# EDMA_TPCC_52A00000h register map
Vendor: Texas Instruments
Registers are 32-bit, read-only, reset 0x0 unless marked. A register's access mark holds for its fields unless they carry their own. Offsets are as the file gives them; [hi:lo] are bit positions; {n}, {i} and the like mark numbered series; 'fields as' and 'values as' point back to an identical list.

## TPCC (part 2 of 2)
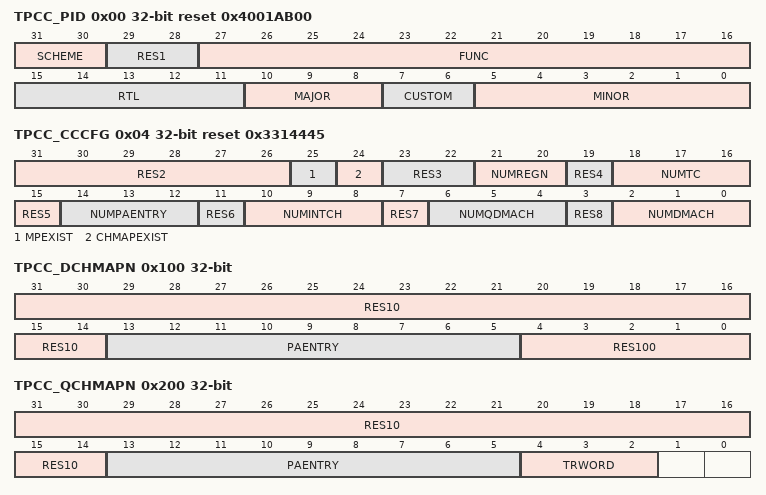
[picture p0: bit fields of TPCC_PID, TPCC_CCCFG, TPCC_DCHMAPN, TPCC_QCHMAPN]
0x00 TPCC_PID reset 0x4001AB00 — Peripheral ID Register
  [31:30] SCHEME — PID Scheme: Used to distinguish between old ID scheme and current. Spare bit to encode future schemes EDMA uses 'new scheme' indicated with value of 0x1.
  [29:28] RES1 — RESERVE FIELD
  [27:16] FUNC — Function indicates a software compatible module family.
  [15:11] RTL — RTL Version
  [10:8] MAJOR — Major Revision
  [7:6] CUSTOM — Custom revision field: Not used on this version of EDMA.
  [5:0] MINOR — Minor Revision
0x04 TPCC_CCCFG reset 0x3314445 — CC Configuration Register
  [31:26] RES2 — RESERVE FIELD
  [25] MPEXIST — Memory Protection Existence MPEXIST =0 : No memory protection. MPEXIST =1 : Memory Protection logic included.
  [24] CHMAPEXIST — Channel Mapping Existence CHMAPEXIST =0 : No Channel mapping. CHMAPEXIST =1 : Channel mapping logic included.
  [23:22] RES3 — RESERVE FIELD
  [21:20] NUMREGN — Number of MP and Shadow regions
  [35-4n] RES{n} (n=4..8) — RESERVE FIELD
  [18:16] NUMTC — Number of Queues/Number of TCs
  [14:12] NUMPAENTRY — Number of PaRAM entries
  [10:8] NUMINTCH — Number of Interrupt Channels
  [6:4] NUMQDMACH — Number of QDMA Channels
  [2:0] NUMDMACH — Number of DMA Channels
0x100 TPCC_DCHMAPN access per field — DMA Channel N mapping to PaRAM.
  [31:14] RES10 ro — RESERVE FIELD
  [13:5] PAENTRY rw — PAENTRY points to the PaRAM Entry number for DMA Channel N
  [4:0] RES100 ro — RESERVE FIELD
0x200 TPCC_QCHMAPN access per field — QDMA Channel N Mapping Register
  [31:14] RES10 ro — RESERVE FIELD
  [13:5] PAENTRY rw — PaRAM Entry number for QDMA Channel N.
  [4:2] TRWORD rw — TRWORD points to the specific trigger word of the PaRAM Entry defined by PAENTRY. A write to the trigger word results in a QDMA Event being recognized.
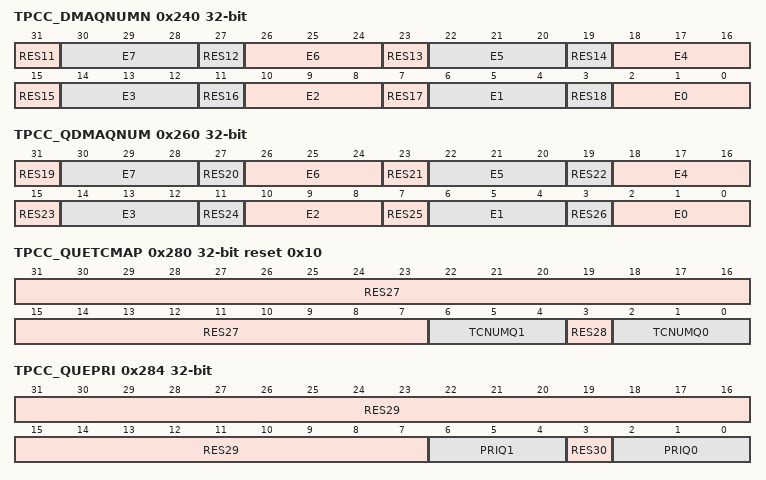
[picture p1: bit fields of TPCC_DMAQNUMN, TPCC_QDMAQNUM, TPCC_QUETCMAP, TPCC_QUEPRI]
0x240 TPCC_DMAQNUMN access per field — DMA Queue Number Register n Contains the Event queue number to be used for the corresponding DMA Channel.
  [75-4n] RES{n} ro (n=11..18) — RESERVE FIELD
  [4n+2:4n] E{n} rw (n=0..7) — DMA Queue Number for event #{n}
0x260 TPCC_QDMAQNUM access per field — QDMA Queue Number Register Contains the Event queue number to be used for the corresponding QDMA Channel.
  [107-4n] RES{n} ro (n=19..26) — RESERVE FIELD
  [4n+2:4n] E{n} rw (n=0..7) — QDMA Queue Number for event #{n}
0x280 TPCC_QUETCMAP access per field reset 0x10 — Queue to TC Mapping
  [31:7] RES27 ro — RESERVE FIELD
  [6:4] TCNUMQ1 rw — TC Number for Queue N: Defines the TC number that Event Queue N TRs are written to.
  [3] RES28 ro — RESERVE FIELD
  [2:0] TCNUMQ0 rw — TC Number for Queue N: Defines the TC number that Event Queue N TRs are written to.
0x284 TPCC_QUEPRI access per field — Queue Priority
  [31:7] RES29 ro — RESERVE FIELD
  [6:4] PRIQ1 rw — Priority Level for Queue 1 Dictates the priority level used for the OPTIONS field programmation for Qn TRs. Sets the priority used for TC read and write commands.
  [3] RES30 ro — RESERVE FIELD
  [2:0] PRIQ0 rw — Priority Level for Queue 0 Dictates the priority level used for the OPTIONS field programmation for Qn TRs. Sets the priority used for TC read and write commands.
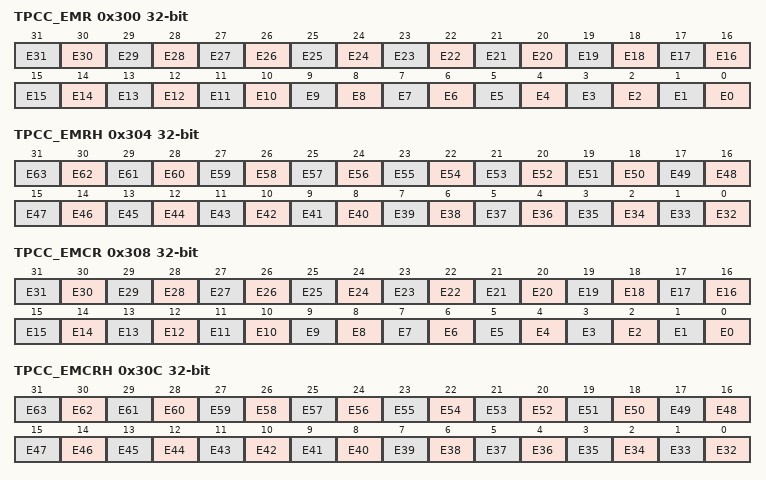
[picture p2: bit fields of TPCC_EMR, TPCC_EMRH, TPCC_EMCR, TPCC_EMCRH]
0x300 TPCC_EMR — Event Missed Register: The Event Missed register is set if 2 events are received without the first event being cleared or if a Null TR is serviced. Chained events (CER) Set Events (ESR) and normal events (ER) are treated individually. If any bit in the EMR register is set (and all errors (including QEMR/CCERR) were previously clear) then an error will be signaled with TPCC error interrupt.
  [n] E{n} (n=0..31) — Event Missed #{n}
0x304 TPCC_EMRH — Event Missed Register (High Part): The Event Missed register is set if 2 events are received without the first event being cleared or if a Null TR is serviced. Chained events (CER) Set Events (ESR) and normal events (ER) are treated individually. If any bit in the EMR register is set (and all errors (including QEMR/CCERR) were previously clear) then an error will be signaled with TPCC error interrupt.
  [n-32] E{n} (n=32..63) — Event Missed #{n}
0x308 TPCC_EMCR wo — Event Missed Clear Register: CPU write of '1' to the EMCR.En bit causes the EMR.En bit to be cleared. CPU write of '0' has no effect.. All error bits must be cleared before additional error interrupts will be asserted by CC.
  [n] E{n} (n=0..31) — Event Missed Clear #{n}
0x30C TPCC_EMCRH wo — Event Missed Clear Register (High Part): CPU write of '1' to the EMCR.En bit causes the EMR.En bit to be cleared. CPU write of '0' has no effect.. All error bits must be cleared before additional error interrupts will be asserted by CC.
  [n-32] E{n} (n=32..63) — Event Missed Clear #{n}
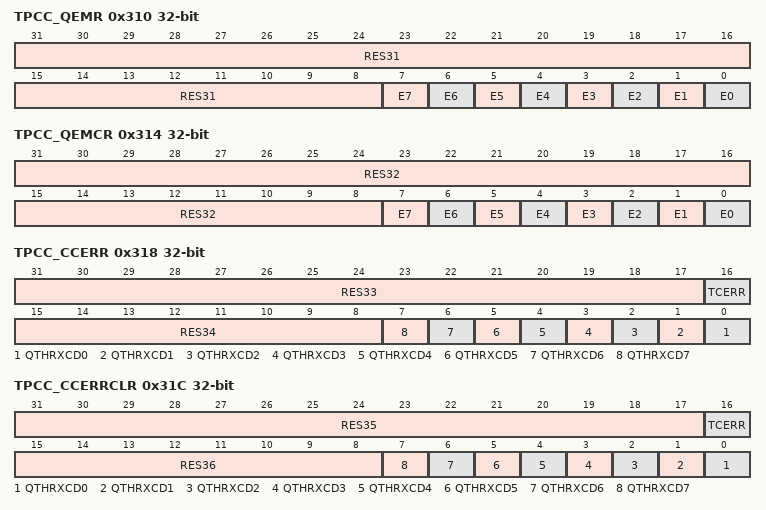
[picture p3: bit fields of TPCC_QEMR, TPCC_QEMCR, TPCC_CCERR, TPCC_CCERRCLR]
0x310 TPCC_QEMR — QDMA Event Missed Register: The QDMA Event Missed register is set if 2 QDMA events are detected without the first event being cleared or if a Null TR is serviced.. If any bit in the QEMR register is set (and all errors (including EMR/CCERR) were previously clear) then an error will be signaled with TPCC error interrupt.
  [31:8] RES31 — RESERVE FIELD
  [n] E{n} (n=0..7) — Event Missed #{n}
0x314 TPCC_QEMCR access per field — QDMA Event Missed Clear Register: CPU write of '1' to the QEMCR.En bit causes the QEMR.En bit to be cleared. CPU write of '0' has no effect.. All error bits must be cleared before additional error interrupts will be asserted by CC.
  [31:8] RES32 ro — RESERVE FIELD
  [n] E{n} wo (n=0..7) — Event Missed Clear #{n}
0x318 TPCC_CCERR — CC Error Register
  [31:17] RES33 — RESERVE FIELD
  [16] TCERR — Transfer Completion Code Error: TCCERR =0 : Total number of allowed TCCs outstanding has not been reached. TCCERR = 1 : Total number of allowed TCCs has been reached. TCCERR can be cleared by Writing a '1' to corresponding bit in CCERRCLR register. If any bit in the CCERR register is set [and all errors were previously clear] then an error will be signaled with TPCC error interrupt.
  [15:8] RES34 — RESERVE FIELD
  [n] QTHRXCD{n} (n=0..7) — Queue Threshold Error for Q{n}: QTHRXCD{n} =0 : Watermark/threshold has not been exceeded. QTHRXCD{n} =1 : Watermark/threshold has been exceeded. CCERR.QTHRXCD{n} can be cleared by Writing a '1' to corresponding bit in CCERRCLR register. If any bit in the CCERR register is set [and all errors [including EMR/QEMR] were previously clear] then an error will be signaled with the TPCC error interrupt.
0x31C TPCC_CCERRCLR access per field — CC Error Clear Register
  [31:17] RES35 ro — RESERVE FIELD
  [16] TCERR wo — Clear Error for CCERR.TCERR: Write of '1' clears the value of CCERR bit N. Writes of '0' have no affect.
  [15:8] RES36 ro — RESERVE FIELD
  [n] QTHRXCD{n} wo (n=0..7) — Clear error for CCERR.QTHRXCD{n}: Write of '1' clears the values of QSTAT{n}.WM QSTAT{n}.THRXCD CCERR.QTHRXCD{n} Writes of '0' have no affect.
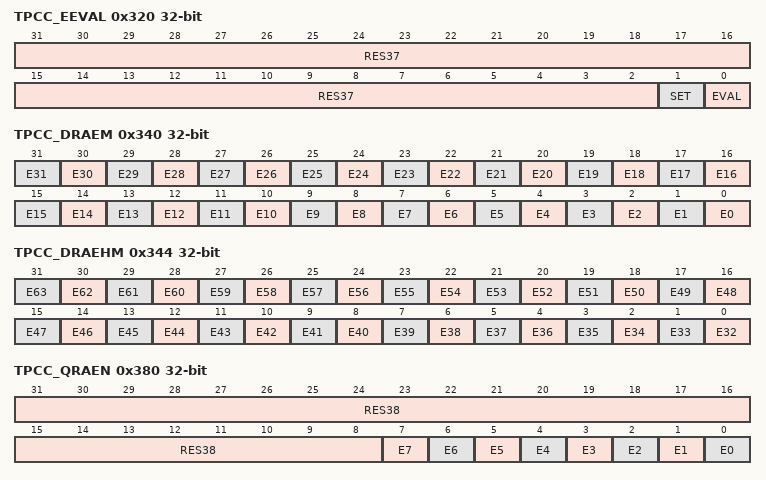
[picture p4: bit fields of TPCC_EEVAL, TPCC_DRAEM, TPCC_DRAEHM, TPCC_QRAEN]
0x320 TPCC_EEVAL access per field — Error Eval Register
  [31:2] RES37 ro — RESERVE FIELD
  [1] SET wo — Error Interrupt Set: CPU write of '1' to the SET bit causes the TPCC error interrupt to be pulsed regardless of state of EMR/EMRH QEMR or CCERR. CPU write of '0' has no effect.
  [0] EVAL wo — Error Interrupt Evaluate: CPU write of '1' to the EVAL bit causes the TPCC error interrupt to be pulsed if any errors have not been cleared in the EMR/EMRH QEMR or CCERR registers. CPU write of '0' has no effect.
0x340 TPCC_DRAEM rw — DMA Region Access enable for bit N in Region M: En = 0 : Accesses via Region M address space to Bit N in any DMA Channel Register are not allowed. Reads will return 'b0 on Bit N and writes will not modify the state of bit N. Enabled interrupt bits for bit N do not contribute to the generation of the TPCC region M interrupt. En = 1 : Accesses via Region M address space to Bit N in any DMA Channel Register are allowed. Reads will return the value from Bit N and writes will modify the state of bit N. Enabled interrupt bits for bit N do contribute to the generation of the TPCC region M interrupt.
  [n] E{n} (n=0..31) — DMA Region Access enable for Region M bit #{n}
0x344 TPCC_DRAEHM rw — DMA Region Access enable for bit N in Region M: En = 0 : Accesses via Region M address space to Bit N in any DMA Channel Register are not allowed. Reads will return 'b0 on Bit N and writes will not modify the state of bit N. Enabled interrupt bits for bit N do not contribute to the generation of the TPCC region M interrupt. En = 1 : Accesses via Region M address space to Bit N in any DMA Channel Register are allowed. Reads will return the value from Bit N and writes will modify the state of bit N. Enabled interrupt bits for bit N do contribute to the generation of the TPCC region M interrupt. En = 0 : Accesses via Region M address space to Bit N in any DMA Channel Register are not allowed. Reads will return 'b0 on Bit N and writes will not modify the state of bit N. Enabled interrupt bits for bit N do not contribute to the generation of the TPCC region M interrupt. En = 1 : Accesses via Region M address space to Bit N in any DMA Channel Register are allowed. Reads will return the value from Bit N and writes will modify the state of bit N. Enabled interrupt bits for bit N do contribute to the generation of the TPCC region M interrupt.
  [n-32] E{n} (n=32..63) — DMA Region Access enable for Region M bit #{n}
0x380 TPCC_QRAEN access per field — QDMA Region Access enable for bit N in Region M: En = 0 : Accesses via Region M address space to Bit N in any QDMA Channel Register are not allowed. Reads will return 'b0 on Bit N and writes will not modify the state of bit N. Enabled interrupt bits for bit N do not contribute to the generation of the TPCC region M interrupt. En = 1 : Accesses via Region M address space to Bit N in any QDMA Channel Register are allowed. Reads will return the value from Bit N and writes will modify the state of bit N. Enabled interrupt bits for bit N do contribute to the generation of the TPCC region n interrupt.
  [31:8] RES38 ro — RESERVE FIELD
  [n] E{n} rw (n=0..7) — QDMA Region Access enable for Region M bit #{n}
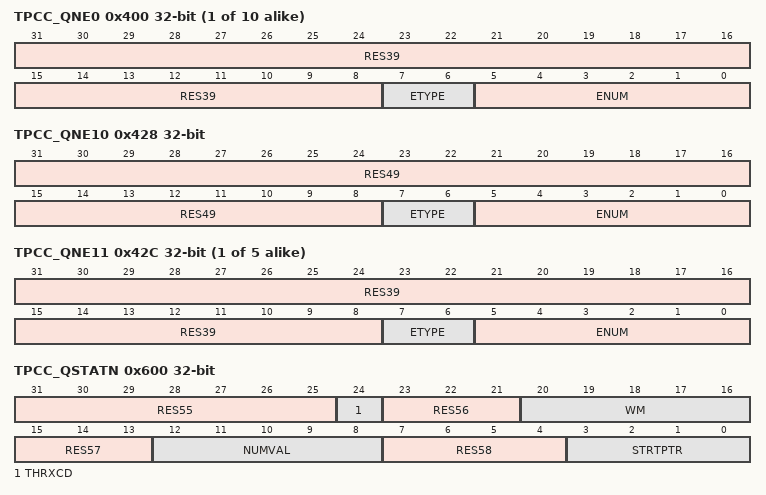
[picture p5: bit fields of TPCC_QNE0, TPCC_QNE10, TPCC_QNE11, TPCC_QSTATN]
{0x400+4i} TPCC_QNE{i} (i=0..9) — Event Queue Entry Diagram for Queue n - Entry {i}
  [31:8] RES{i+39} — RESERVE FIELD
  [7:6] ETYPE — Event Type: Specifies the specific Event Type for the given entry in the Event Queue.
  [5:0] ENUM — Event Number: Specifies the specific Event Number for the given entry in the Event Queue. For DMA Channel events [ER/ESR/CER] ENUM will range between 0 and NUM_DMACH [up to 63]. For QDMA Channel events [QER] ENUM will range between 0 and NUM_QDMACH [up to 7].
0x428 TPCC_QNE10 — Event Queue Entry Diagram for Queue n - Entry 0
  [31:8] RES49 — RESERVE FIELD
  [7:6] ETYPE — Event Type: Specifies the specific Event Type for the given entry in the Event Queue.
  [5:0] ENUM — Event Number: Specifies the specific Event Number for the given entry in the Event Queue. For DMA Channel events [ER/ESR/CER] ENUM will range between 0 and NUM_DMACH [up to 63]. For QDMA Channel events [QER] ENUM will range between 0 and NUM_QDMACH [up to 7].
{0x400+4i} TPCC_QNE{i} (i=11..15) — Event Queue Entry Diagram for Queue n - Entry {i}
  fields as TPCC_QNE0
0x600 TPCC_QSTATN — QSTATn Register Set
  [31:25] RES55 — RESERVE FIELD
  [24] THRXCD — Threshold Exceeded: THRXCD =0 : Threshold specified by QWMTHR[A B].Qn has not been exceeded. THRXCD =1 : Threshold specified by QWMTHR[A B].Qn has been exceeded. QSTATn.THRXCD is cleared via CCERR.WMCLRn bit.
  [23:21] RES56 — RESERVE FIELD
  [20:16] WM — Watermark for Maximum Queue Usage: Watermark tracks the most entries that have been in QueueN since reset or since the last time that the watermark [WM] was cleared. QSTATn.WM is cleared via CCERR.WMCLRn bit. Legal values = 0x0 [empty] to 0x10 [full]
  [15:13] RES57 — RESERVE FIELD
  [12:8] NUMVAL — Number of Valid Entries in QueueN: Represents the total number of entries residing in the Queue Manager FIFO at a given instant. Always enabled. Legal values = 0x0 [empty] to 0x10 [full]
  [7:4] RES58 — RESERVE FIELD
  [3:0] STRTPTR — Start Pointer: Represents the offset to the head entry of QueueN in units of entries. Always enabled. Legal values = 0x0 [0th entry] to 0xF [15th entry]
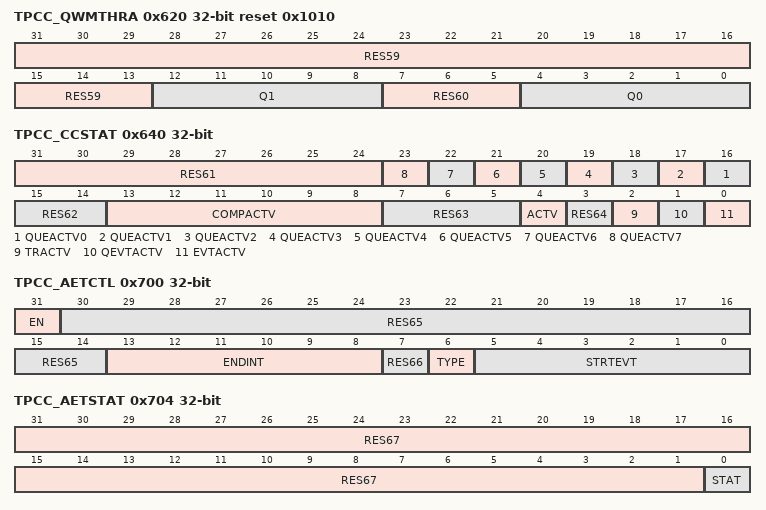
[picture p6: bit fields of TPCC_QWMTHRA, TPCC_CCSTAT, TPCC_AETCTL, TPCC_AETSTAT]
0x620 TPCC_QWMTHRA access per field reset 0x1010 — Queue Threshold A for Q[3:0]: CCERR.QTHRXCDn and QSTATn.THRXCD error bit is set when the number of Events in QueueN at an instant in time (visible via QSTATn.NUMVAL) equals or exceeds the value specified by QWMTHRA.Qn. Legal values = 0x0 (ever used?) to 0x10 (ever full?) A value of 0x11 disables threshold errors.
  [31:13] RES59 ro — RESERVE FIELD
  [12:8] Q1 rw — Queue Threshold for Q1 value
  [7:5] RES60 ro — RESERVE FIELD
  [4:0] Q0 rw — Queue Threshold for Q0 value
0x640 TPCC_CCSTAT — CC Status Register
  [31:24] RES61 — RESERVE FIELD
  [n+16] QUEACTV{n} (n=0..7) — Queue {n} Active QUEACTV{n} =0 : No Evts are queued in Q{n}. QUEACTV{n} =1 : At least one TR is queued in Q{n}.
  [15:14] RES62 — RESERVE FIELD
  [13:8] COMPACTV — Completion Request Active: Counter that tracks the total number of completion requests submitted to the TC. The counter increments when a TR is submitted with TCINTEN or TCCHEN set to '1'. The counter decrements for every valid completion code received from any of the external TCs. The CC will not service new TRs if COMPACTV count is already at the limit. COMPACTV =0 : No completion requests outstanding. COMPACTV =1:Total of '1' completion request outstanding. ... COMPACTV =63 : Total of 63 completion requests are outstanding. No additional TRs will be submitted until count is less than 63.
  [7:5] RES63 — RESERVE FIELD
  [4] ACTV — Channel Controller Active: Channel Controller Active is a logical-OR of each of the ACTV signals. The ACTV bit must remain high through the life of a TR. ACTV =0 : Channel is idle. ACTV =1 : Channel is busy.
  [3] RES64 — RESERVE FIELD
  [2] TRACTV — Transfer Request Active: TRACTV =0 : Transfer Request processing/submission logic is inactive. TRACTV =1 : Transfer Request processing/submission logic is active.
  [1] QEVTACTV — QDMA Event Active: QEVTACTV =0 : No enabled QDMA Events are active within the CC. QEVTACTV =1 : At least one enabled DMA Event [ER & EER ESR CER] is active within the CC.
  [0] EVTACTV — DMA Event Active: EVTACTV =0 : No enabled DMA Events are active within the CC. EVTACTV =1 : At least one enabled DMA Event [ER & EER ESR CER] is active within the CC.
0x700 TPCC_AETCTL access per field — Advanced Event Trigger Control
  [31] EN rw — AET Enable: EN =0 : AET event generation is disabled. EN = 1 : AET event generation is enabled.
  [30:14] RES65 ro — RESERVE FIELD
  [13:8] ENDINT rw — AET End Interrupt: Dictates the completion interrupt number that will force the tpcc_aet signal to be deasserted [low]
  [7] RES66 ro — RESERVE FIELD
  [6] TYPE rw — AET Event Type: TYPE =0 : Event specified by STARTEVT applies to DMA Events [set by ER ESR or CER] TYPE =1 : Event specified by STARTEVT applies to QDMA Events
  [5:0] STRTEVT rw — AET Start Event: Dictates the Event Number that will force the tpcc_aet signal to be asserted [high]
0x704 TPCC_AETSTAT — Advanced Event Trigger Stat
  [31:1] RES67 — RESERVE FIELD
  [0] STAT — AET Status: AETSTAT =0 : tpcc_aet is currently low. AETSTAT =1 : tpcc_aet is currently high.
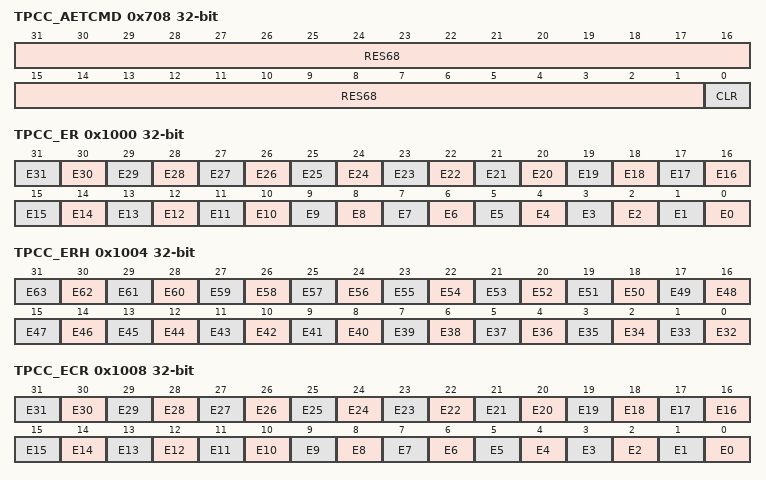
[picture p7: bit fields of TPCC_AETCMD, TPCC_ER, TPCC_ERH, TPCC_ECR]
0x708 TPCC_AETCMD access per field — AET Command
  [31:1] RES68 ro — RESERVE FIELD
  [0] CLR wo — AET Clear command: CPU write of '1' to the CLR bit causes the tpcc_aet output signal and AETSTAT.STAT register to be cleared. CPU write of '0' has no effect..
0x1000 TPCC_ER — Event Register: If ER.En bit is set and the EER.En bit is also set then the corresponding DMA channel is prioritized vs. other pending DMA events for submission to the TC. ER.En bit is set when the input event #n transitions from inactive (low) to active (high) regardless of the state of EER.En bit. ER.En bit is cleared when the corresponding event is prioritized and serviced. If the ER.En bit is already set and a new inactive to active transition is detected on the input event #n input AND the corresponding bit in the EER register is set then the corresponding bit in the Event Missed Register is set. Event N can be cleared via sw by writing a '1' to the ECR pseudo-register.
  [n] E{n} (n=0..31) — Event #{n}
0x1004 TPCC_ERH — Event Register (High Part): If ERH.En bit is set and the EERH.En bit is also set then the corresponding DMA channel is prioritized vs. other pending DMA events for submission to the TC. ERH.En bit is set when the input event #n transitions from inactive (low) to active (high) regardless of the state of EERH.En bit. ER.En bit is cleared when the corresponding event is prioritized and serviced. If the ERH.En bit is already set and a new inactive to active transition is detected on the input event #n input AND the corresponding bit in the EERH register is set then the corresponding bit in the Event Missed Register is set. Event N can be cleared via sw by writing a '1' to the ECRH pseudo-register.
  [n-32] E{n} (n=32..63) — Event #{n}
0x1008 TPCC_ECR wo — Event Clear Register: CPU write of '1' to the ECR.En bit causes the ER.En bit to be cleared. CPU write of '0' has no effect.
  [n] E{n} (n=0..31) — Event #{n}
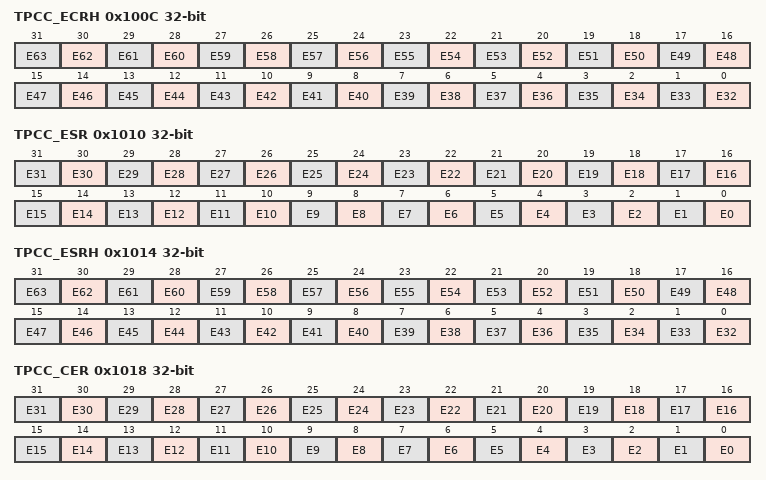
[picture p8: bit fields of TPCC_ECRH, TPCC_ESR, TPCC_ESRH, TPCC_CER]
0x100C TPCC_ECRH wo — Event Clear Register (High Part): CPU write of '1' to the ECRH.En bit causes the ERH.En bit to be cleared. CPU write of '0' has no effect.
  [n-32] E{n} (n=32..63) — Event #{n}
0x1010 TPCC_ESR wo — Event Set Register: CPU write of '1' to the ESR.En bit causes the ER.En bit to be set. CPU write of '0' has no effect.
  [n] E{n} (n=0..31) — Event #{n}
0x1014 TPCC_ESRH wo — Event Set Register (High Part) CPU write of '1' to the ESRH.En bit causes the ERH.En bit to be set. CPU write of '0' has no effect.
  [n-32] E{n} (n=32..63) — Event #{n}
0x1018 TPCC_CER — Chained Event Register: If CER.En bit is set (regardless of state of EER.En) then the corresponding DMA channel is prioritized vs. other pending DMA events for submission to the TC. CER.En bit is set when a chaining completion code is returned from one of the 3PTCs via the completion interface or is generated internally via Early Completion path. CER.En bit is cleared when the corresponding event is prioritized and serviced. If the CER.En bit is already set and the corresponding chaining completion code is returned from the TC then the corresponding bit in the Event Missed Register is set. CER.En cannot be set or cleared via software.
  [n] E{n} (n=0..31) — Event #{n}
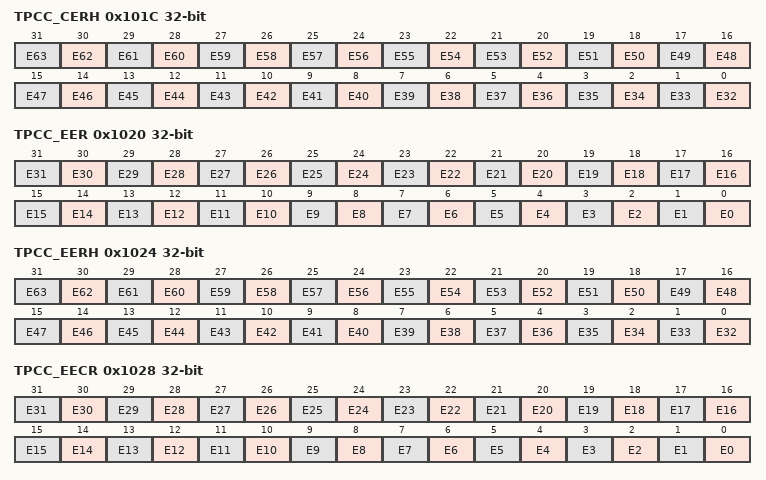
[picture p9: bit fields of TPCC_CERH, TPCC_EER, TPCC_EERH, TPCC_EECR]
0x101C TPCC_CERH — Chained Event Register (High Part): If CERH.En bit is set (regardless of state of EERH.En) then the corresponding DMA channel is prioritized vs. other pending DMA events for submission to the TC. CERH.En bit is set when a chaining completion code is returned from one of the 3PTCs via the completion interface or is generated internally via Early Completion path. CERH.En bit is cleared when the corresponding event is prioritized and serviced. If the CERH.En bit is already set and the corresponding chaining completion code is returned from the TC then the corresponding bit in the Event Missed Register is set. CERH.En cannot be set or cleared via software.
  [n-32] E{n} (n=32..63) — Event #{n}
0x1020 TPCC_EER — Event Enable Register: Enables DMA transfers for ER.En pending events. ER.En is set based on externally asserted events (via tpcc_eventN_pi). This register has no effect on Chained Event Register (CER) or Event Set Register (ESR). Note that if a bit is set in ER.En while EER.En is disabled no action is taken. If EER.En is enabled at a later point (and ER.En has not been cleared via SW) then the event will be recognized as a valid 'TR Sync' EER.En is not directly writeable. Events can be enabled via writes to EESR and can be disabled via writes to EECR register. EER.En = 0: ER.En is not enabled to trigger DMA transfers. EER.En = 1: ER.En is enabled to trigger DMA transfers.
  [n] E{n} (n=0..31) — Event #{n}
0x1024 TPCC_EERH — Event Enable Register (High Part): Enables DMA transfers for ERH.En pending events. ERH.En is set based on externally asserted events (via tpcc_eventN_pi). This register has no effect on Chained Event Register (CERH) or Event Set Register (ESRH). Note that if a bit is set in ERH.En while EERH.En is disabled no action is taken. If EERH.En is enabled at a later point (and ERH.En has not been cleared via SW) then the event will be recognized as a valid 'TR Sync' EERH.En is not directly writeable. Events can be enabled via writes to EESRH and can be disabled via writes to EECRH register. EERH.En = 0: ER.En is not enabled to trigger DMA transfers. EERH.En = 1: ER.En is enabled to trigger DMA transfers.
  [n-32] E{n} (n=32..63) — Event #{n}
0x1028 TPCC_EECR wo — Event Enable Clear Register: CPU write of '1' to the EECR.En bit causes the EER.En bit to be cleared. CPU write of '0' has no effect..
  [n] E{n} (n=0..31) — Event #{n}
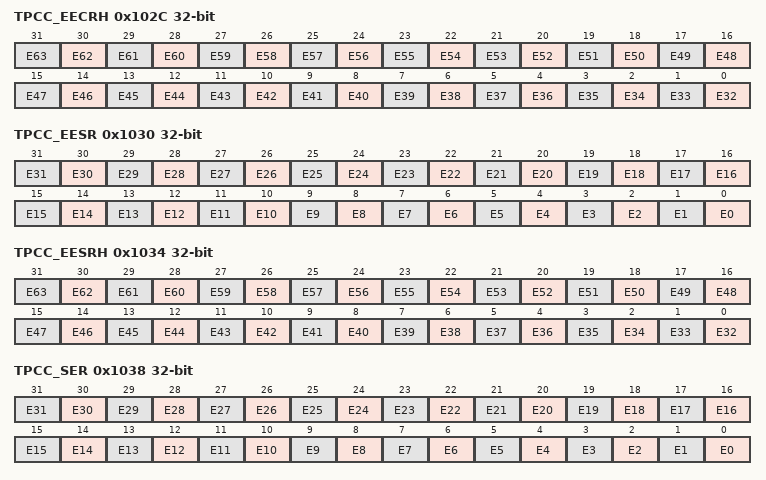
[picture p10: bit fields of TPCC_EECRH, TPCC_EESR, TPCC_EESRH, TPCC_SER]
0x102C TPCC_EECRH wo — Event Enable Clear Register (High Part): CPU write of '1' to the EECRH.En bit causes the EERH.En bit to be cleared. CPU write of '0' has no effect..
  [n-32] E{n} (n=32..63) — Event #{n}
0x1030 TPCC_EESR wo — Event Enable Set Register: CPU write of '1' to the EESR.En bit causes the EER.En bit to be set. CPU write of '0' has no effect..
  [n] E{n} (n=0..31) — Event #{n}
0x1034 TPCC_EESRH wo — Event Enable Set Register (High Part): CPU write of '1' to the EESRH.En bit causes the EERH.En bit to be set. CPU write of '0' has no effect..
  [n-32] E{n} (n=32..63) — Event #{n}
0x1038 TPCC_SER — Secondary Event Register: The secondary event register is used along with the Event Register (ER) to provide information on the state of an Event. En = 0 : Event is not currently in the Event Queue. En = 1 : Event is currently stored in Event Queue. Event arbiter will not prioritize additional events.
  [n] E{n} (n=0..31) — Event #{n}
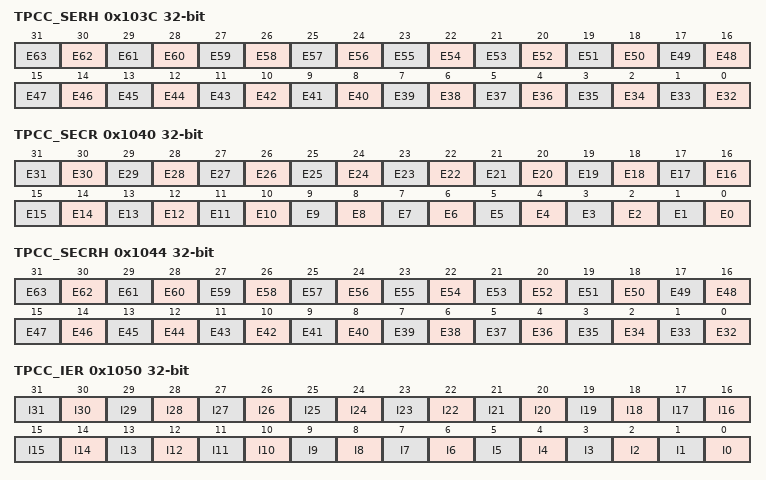
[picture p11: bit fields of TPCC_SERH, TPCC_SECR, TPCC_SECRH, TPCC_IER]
0x103C TPCC_SERH — Secondary Event Register (High Part): The secondary event register is used along with the Event Register (ERH) to provide information on the state of an Event. En = 0 : Event is not currently in the Event Queue. En = 1 : Event is currently stored in Event Queue. Event arbiter will not prioritize additional events.
  [n-32] E{n} (n=32..63) — Event #{n}
0x1040 TPCC_SECR wo — Secondary Event Clear Register: The secondary event clear register is used to clear the status of the SER registers. CPU write of '1' to the SECR.En bit clears the SER register. CPU write of '0' has no effect.
  [n] E{n} (n=0..31) — Event #{n}
0x1044 TPCC_SECRH wo — Secondary Event Clear Register (High Part): The secondary event clear register is used to clear the status of the SERH registers. CPU write of '1' to the SECRH.En bit clears the SERH register. CPU write of '0' has no effect.
  [n-32] E{n} (n=32..63) — Event #{n}
0x1050 TPCC_IER — Int Enable Register: IER.In is not directly writeable. Interrupts can be enabled via writes to IESR and can be disabled via writes to IECR register. IER.In = 0: IPR.In is NOT enabled for interrupts. IER.In = 1: IPR.In IS enabled for interrupts.
  [n] I{n} (n=0..31) — Interrupt associated with TCC #{n}
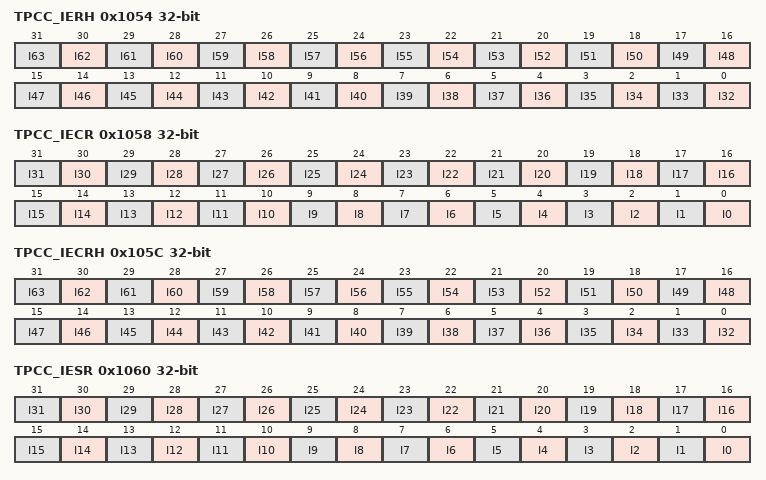
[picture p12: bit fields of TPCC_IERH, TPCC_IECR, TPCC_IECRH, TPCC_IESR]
0x1054 TPCC_IERH — Int Enable Register (High Part): IERH.In is not directly writeable. Interrupts can be enabled via writes to IESRH and can be disabled via writes to IECRH register. IERH.In = 0: IPRH.In is NOT enabled for interrupts. IERH.In = 1: IPRH.In IS enabled for interrupts.
  [n-32] I{n} (n=32..63) — Interrupt associated with TCC #{n}
0x1058 TPCC_IECR wo — Int Enable Clear Register: CPU write of '1' to the IECR.In bit causes the IER.In bit to be cleared. CPU write of '0' has no effect..
  [n] I{n} (n=0..31) — Interrupt associated with TCC #{n}
0x105C TPCC_IECRH wo — Int Enable Clear Register (High Part): CPU write of '1' to the IECRH.In bit causes the IERH.In bit to be cleared. CPU write of '0' has no effect..
  [n-32] I{n} (n=32..63) — Interrupt associated with TCC #{n}
0x1060 TPCC_IESR wo — Int Enable Set Register: CPU write of '1' to the IESR.In bit causes the IESR.In bit to be set. CPU write of '0' has no effect..
  [n] I{n} (n=0..31) — Interrupt associated with TCC #{n}
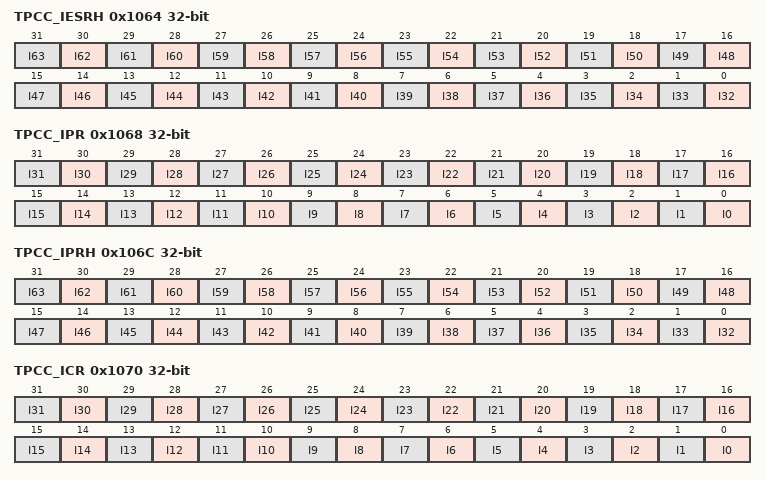
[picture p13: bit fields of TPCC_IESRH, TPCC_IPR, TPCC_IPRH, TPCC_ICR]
0x1064 TPCC_IESRH wo — Int Enable Set Register (High Part): CPU write of '1' to the IESRH.In bit causes the IESRH.In bit to be set. CPU write of '0' has no effect..
  [n-32] I{n} (n=32..63) — Interrupt associated with TCC #{n}
0x1068 TPCC_IPR — Interrupt Pending Register: IPR.In bit is set when a interrupt completion code with TCC of N is detected. IPR.In bit is cleared via software by writing a '1' to ICR.In bit.
  [n] I{n} (n=0..31) — Interrupt associated with TCC #{n}
0x106C TPCC_IPRH — Interrupt Pending Register (High Part): IPRH.In bit is set when a interrupt completion code with TCC of N is detected. IPRH.In bit is cleared via software by writing a '1' to ICRH.In bit.
  [n-32] I{n} (n=32..63) — Interrupt associated with TCC #{n}
0x1070 TPCC_ICR wo — Interrupt Clear Register: CPU write of '1' to the ICR.In bit causes the IPR.In bit to be cleared. CPU write of '0' has no effect. All IPR.In bits must be cleared before additional interrupts will be asserted by CC.
  [n] I{n} (n=0..31) — Interrupt associated with TCC #{n}
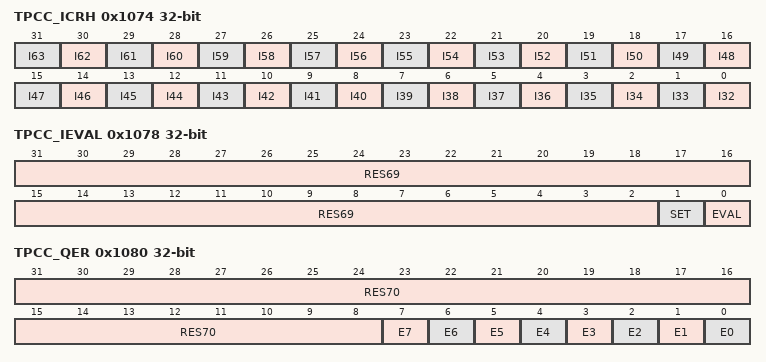
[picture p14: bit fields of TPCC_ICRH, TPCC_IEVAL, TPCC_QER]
0x1074 TPCC_ICRH wo — Interrupt Clear Register (High Part): CPU write of '1' to the ICRH.In bit causes the IPRH.In bit to be cleared. CPU write of '0' has no effect. All IPRH.In bits must be cleared before additional interrupts will be asserted by CC.
  [n-32] I{n} (n=32..63) — Interrupt associated with TCC #{n}
0x1078 TPCC_IEVAL access per field — Interrupt Eval Register
  [31:2] RES69 ro — RESERVE FIELD
  [1] SET wo — Interrupt Set: CPU write of '1' to the SETn bit causes the tpcc_intN output signal to be pulsed egardless of state of interrupts enable [IERn] and status [IPRn]. CPU write of '0' has no effect.
  [0] EVAL wo — Interrupt Evaluate: CPU write of '1' to the EVALn bit causes the tpcc_intN output signal to be pulsed if any enabled interrupts [IERn] are still pending [IPRn]. CPU write of '0' has no effect..
0x1080 TPCC_QER — QDMA Event Register: If QER.En bit is set then the corresponding QDMA channel is prioritized vs. other qdma events for submission to the TC. QER.En bit is set when a vbus write byte matches the address defined in the QCHMAPn register. QER.En bit is cleared when the corresponding event is prioritized and serviced. QER.En is also cleared when user writes a '1' to the QSECR.En bit. If the QER.En bit is already set and a new QDMA event is detected due to user write to QDMA trigger location and QEER register is set then the corresponding bit in the QDMA Event Missed Register is set.
  [31:8] RES70 — RESERVE FIELD
  [n] E{n} (n=0..7) — Event #{n}
